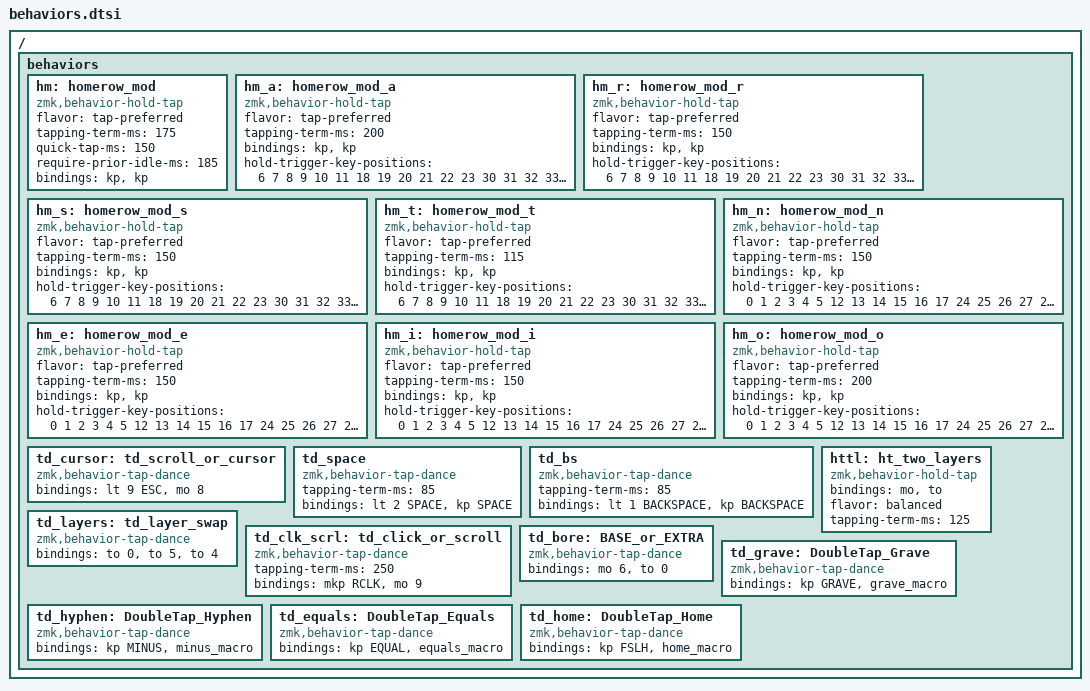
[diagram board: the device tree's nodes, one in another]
/ {
    behaviors {
        hm: homerow_mod {
            compatible = "zmk,behavior-hold-tap";
            #binding-cells = <2>;
            flavor = "tap-preferred";
            tapping-term-ms = <175>; // triggers the hold behavior when the tapping-term-ms has expired
            quick-tap-ms = <150>; // If you press a tapped hold-tap again within quick-tap-ms milliseconds of the first press, it will always trigger the tap behavior.
            require-prior-idle-ms = <185>; // like quick-tap-ms however it will apply for any non-modifier key pressed before it
            bindings = <&kp>, <&kp>;  // hold, tap
        };

        // tapping-term-ms = <150>;  // <---[[produces hold if held longer than tapping-term-ms]]
        // quick-tap-ms = <15.>;  // <---[[double tap within quick-tap-ms will trigger the tap behavior]]
        // require-prior-idle-ms = <185>; // like quick-tap-ms however it will apply for any non-modifier key pressed before it
        // flavor = "tap-unless-interrupted";  // <---[[changes tapping-term-ms to acivate a tap]]

        hm_a: homerow_mod_a {
            compatible = "zmk,behavior-hold-tap";
            #binding-cells = <2>;
            flavor = "tap-preferred";
            tapping-term-ms = <200>;
            bindings = <&kp>, <&kp>;
            hold-trigger-key-positions = <6 7 8 9 10 11 18 19 20 21 22 23 30 31 32 33 34 35 39 40 16 15 14 12>;
        };

        hm_r: homerow_mod_r {
            compatible = "zmk,behavior-hold-tap";
            #binding-cells = <2>;
            flavor = "tap-preferred";
            tapping-term-ms = <150>;
            bindings = <&kp>, <&kp>;
            hold-trigger-key-positions = <6 7 8 9 10 11 18 19 20 21 22 23 30 31 32 33 34 35 39 40 16 15 14 12>;
        };

        hm_s: homerow_mod_s {
            compatible = "zmk,behavior-hold-tap";
            #binding-cells = <2>;
            flavor = "tap-preferred";
            tapping-term-ms = <150>;
            bindings = <&kp>, <&kp>;
            hold-trigger-key-positions = <6 7 8 9 10 11 18 19 20 21 22 23 30 31 32 33 34 35 39 40 16 15 14 12>;
        };

        hm_t: homerow_mod_t {
            compatible = "zmk,behavior-hold-tap";
            #binding-cells = <2>;
            flavor = "tap-preferred";
            tapping-term-ms = <115>;
            bindings = <&kp>, <&kp>;
            hold-trigger-key-positions = <6 7 8 9 10 11 18 19 20 21 22 23 30 31 32 33 34 35 39 40 16 15 14 12>;
        };

        hm_n: homerow_mod_n {
            compatible = "zmk,behavior-hold-tap";
            #binding-cells = <2>;
            flavor = "tap-preferred";
            tapping-term-ms = <150>;
            bindings = <&kp>, <&kp>;
            hold-trigger-key-positions = <0 1 2 3 4 5 12 13 14 15 16 17 24 25 26 27 28 29 36 37 38 19 20 21 22>;
        };

        hm_e: homerow_mod_e {
            compatible = "zmk,behavior-hold-tap";
            #binding-cells = <2>;
            flavor = "tap-preferred";
            tapping-term-ms = <150>;
            bindings = <&kp>, <&kp>;
            hold-trigger-key-positions = <0 1 2 3 4 5 12 13 14 15 16 17 24 25 26 27 28 29 36 37 38 19 20 21 22>;
        };

        hm_i: homerow_mod_i {
            compatible = "zmk,behavior-hold-tap";
            #binding-cells = <2>;
            flavor = "tap-preferred";
            tapping-term-ms = <150>;
            bindings = <&kp>, <&kp>;
            hold-trigger-key-positions = <0 1 2 3 4 5 12 13 14 15 16 17 24 25 26 27 28 29 36 37 38 19 20 21 22>;
        };

        hm_o: homerow_mod_o {
            compatible = "zmk,behavior-hold-tap";
            #binding-cells = <2>;
            flavor = "tap-preferred";
            tapping-term-ms = <200>;
            bindings = <&kp>, <&kp>;
            hold-trigger-key-positions = <0 1 2 3 4 5 12 13 14 15 16 17 24 25 26 27 28 29 36 37 38 19 20 21 22>;
        };

        td_cursor: td_scroll_or_cursor {
            compatible = "zmk,behavior-tap-dance";
            #binding-cells = <0>;
            bindings = <&lt 9 ESC>, <&mo 8>; // hold, tap, double_tap
        };

        td_space: td_space {
            compatible = "zmk,behavior-tap-dance";
            #binding-cells = <0>;
            tapping-term-ms = <85>;
            bindings = <&lt 2 SPACE>, <&kp SPACE>; // hold, tap, double_tap
        };

        td_bs: td_bs {
            compatible = "zmk,behavior-tap-dance";
            #binding-cells = <0>;
            tapping-term-ms = <85>;
            bindings = <&lt 1 BACKSPACE>, <&kp BACKSPACE>; // hold, tap, double_tap
        };

        httl: ht_two_layers {
            compatible = "zmk,behavior-hold-tap";
            bindings = <&mo>, <&to>;
            #binding-cells = <2>;
            flavor = "balanced";
            tapping-term-ms = <125>;
        };

        td_layers: td_layer_swap {
            compatible = "zmk,behavior-tap-dance";
            #binding-cells = <0>;
            bindings = <&to 0>, <&to 5>, <&to 4>; // tap, double_tap, tripple_tap
        };

        td_clk_scrl: td_click_or_scroll {
            compatible = "zmk,behavior-tap-dance";
            #binding-cells = <0>;
            tapping-term-ms = <250>;
            bindings = <&mkp RCLK>, <&mo 9>;  // tap/hold, double_tap
        };

        td_bore: BASE_or_EXTRA {
            compatible = "zmk,behavior-tap-dance";
            #binding-cells = <0>;
            bindings = <&mo 6>, <&to 0>;
        };

        td_grave: DoubleTap_Grave {
            compatible = "zmk,behavior-tap-dance";
            #binding-cells = <0>;
            bindings = <&kp GRAVE>, <&grave_macro>;
        };

        td_hyphen: DoubleTap_Hyphen {
            compatible = "zmk,behavior-tap-dance";
            #binding-cells = <0>;
            bindings = <&kp MINUS>, <&minus_macro>;
        };

        td_equals: DoubleTap_Equals {
            compatible = "zmk,behavior-tap-dance";
            #binding-cells = <0>;
            bindings = <&kp EQUAL>, <&equals_macro>;
        };

        td_home: DoubleTap_Home {
            compatible = "zmk,behavior-tap-dance";
            #binding-cells = <0>;
            bindings = <&kp FSLH>, <&home_macro>;
        };
    };
};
